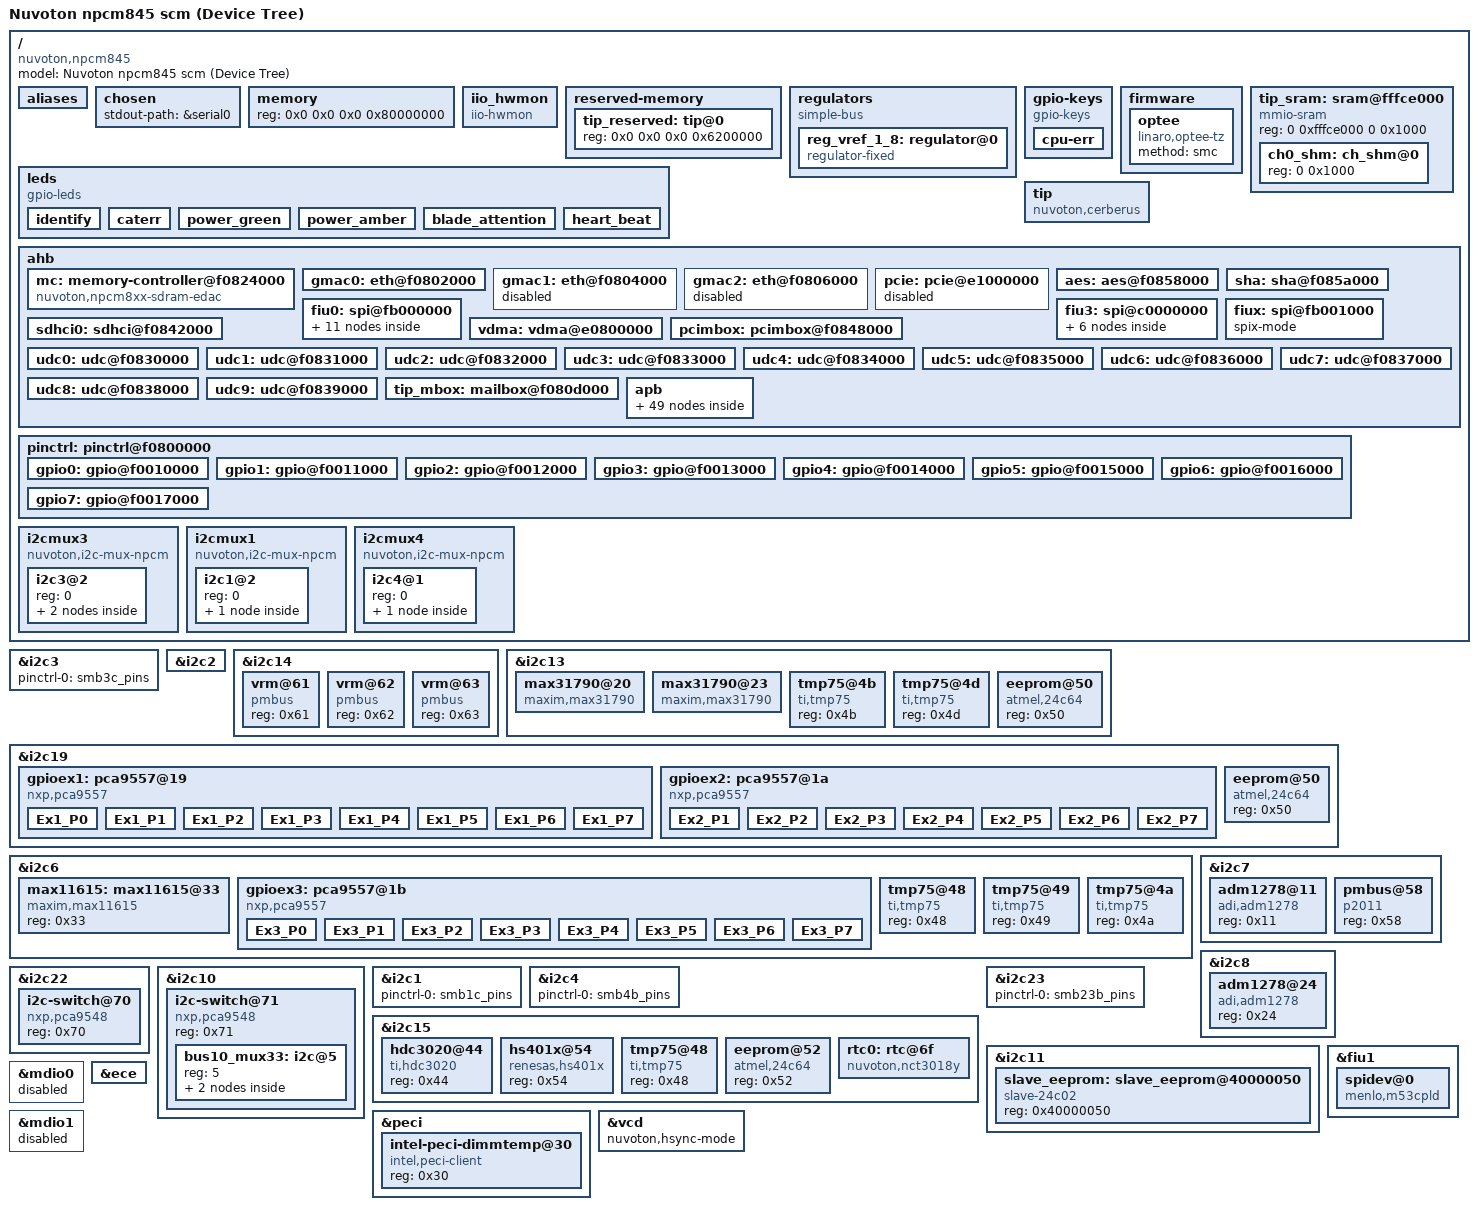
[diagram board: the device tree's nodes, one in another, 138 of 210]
// SPDX-License-Identifier: GPL-2.0
// Copyright (c) 2018 Nuvoton Technology tomer.maimon@nuvoton.com
// Copyright 2018 Google, Inc.

/dts-v1/;
#include "nuvoton-npcm845.dtsi"
#include "nuvoton-npcm845-pincfg-evb.dtsi"
#include <dt-bindings/thermal/thermal.h>
#include <dt-bindings/i2c/i2c.h>

/ {
	model = "Nuvoton npcm845 scm (Device Tree)";
	compatible = "nuvoton,npcm845";

	aliases {
		serial0 = &serial0;
		serial1 = &serial1;
		serial2 = &serial2;
		serial3 = &serial3;
		serial4 = &serial4;
		serial5 = &serial5;
		ethernet0 = &gmac0;
		ethernet1 = &gmac2;
		udc0 = &udc0;
		udc1 = &udc1;
		udc2 = &udc2;
		udc3 = &udc3;
		udc4 = &udc4;
		udc5 = &udc5;
		udc6 = &udc6;
		udc7 = &udc7;
		udc8 = &udc8;
		udc9 = &udc9;
		i2c1 = &i2c3;
		i2c2 = &i2c2;
		i2c3 = &i2c14;
		i2c4 = &i2c13;
		i2c5 = &i2c19;
		i2c6 = &i2c6;
		i2c7 = &i2c7;
		i2c8 = &i2c8;
		i2c9 = &i2c22;
		i2c10 = &i2c10;
		i2c11 = &i2c1;
		i2c12 = &i2c4;
		i2c15 = &i2c15;
		i2c16 = &i2c23;
		i2c17 = &i2c11;
		fiu0 = &fiu0;
		fiu1 = &fiu3;
		fiu2 = &fiux;
		fiu3 = &fiu1;
	};

	chosen {
		stdout-path = &serial0;
	};

	memory {
		reg = <0x0 0x0 0x0 0x80000000>;
	};

	iio_hwmon {
		compatible = "iio-hwmon";
		io-channels = <&adc 0>, <&adc 1>, <&adc 2>, <&adc 3>,
			      <&max11615 0>, <&max11615 1>, <&max11615 2>,
			      <&max11615 3>, <&max11615 4>, <&max11615 5>,
			      <&max11615 6>, <&max11615 7>;
	};

	reserved-memory {
		#address-cells = <2>;
		#size-cells = <2>;
		ranges;

		tip_reserved: tip@0 {
		reg = <0x0 0x0 0x0 0x6200000>;
		};

	};

	regulators {
		compatible = "simple-bus";
		#address-cells = <1>;
		#size-cells = <0>;

		reg_vref_1_8: regulator@0 {
			compatible = "regulator-fixed";
			reg = <0>;
			regulator-name = "vref_1_8v";
			regulator-min-microvolt = <1800000>;
			regulator-max-microvolt = <1800000>;
		};
	};

	leds {
		compatible = "gpio-leds";

		identify {
			label = "identify";
			gpios = <&gpio1 30 GPIO_ACTIVE_HIGH>; /* gpio62 */
		};

		caterr {
			label = "caterr";
			gpios = <&gpio2 12 GPIO_ACTIVE_HIGH>; /* gpio76 */
		};

		power_green {
			label = "power_green";
			gpios = <&gpio1 12 GPIO_ACTIVE_HIGH>; /* gpio44 */
		};

		power_amber {
			label = "power_amber";
			gpios = <&gpio1 13 GPIO_ACTIVE_HIGH>; /* gpio45 */
		};

		blade_attention {
			label = "blade_attention";
			gpios = <&gpio1 14 GPIO_ACTIVE_HIGH>; /* gpio46 */
		};

		heart_beat {
			label = "heart_beat";
			gpios = <&gpio7 4 GPIO_ACTIVE_HIGH>; /* gpio228 */
		};
	};

	gpio-keys {
		compatible = "gpio-keys";
		cpu-err {
			label = "cpu-err";
			gpios = <&gpio2 12 GPIO_ACTIVE_LOW>;
			linux,code = <27>;
		};
	};

	firmware {
		optee {
			compatible = "linaro,optee-tz";
			method = "smc";
		};
	};

	tip_sram: sram@fffce000 {
		compatible = "mmio-sram";
		reg = <0 0xfffce000 0 0x1000>;
		#address-cells = <1>;
		#size-cells = <1>;
		ranges = <0 0 0xfffce000 0x1000>;
		ch0_shm: ch_shm@0 {
			reg = <0 0x1000>;
		};
	};

	tip {
		compatible = "nuvoton,cerberus";
		mboxes = <&tip_mbox 0 16>; /*channel 0, 16th doorbell */
		mbox-names = "cerberus";
		shmem = <&ch0_shm>;
		status = "okay";
	};

	ahb {
		mc: memory-controller@f0824000 {
			compatible = "nuvoton,npcm8xx-sdram-edac";
			reg = <0x0 0xf0824000 0x0 0x1000>;
			interrupts = <GIC_SPI 25 IRQ_TYPE_LEVEL_HIGH>;
			status = "okay";
		};


		gmac0: eth@f0802000 {
			phy-mode = "sgmii";
			npcm,sgmii-an;
			snps,eee-force-disable;
			status = "okay";
		};

		gmac1: eth@f0804000 {
			phy-mode = "rgmii-id";
			snps,eee-force-disable;
			status = "disable";
		};

		gmac2: eth@f0806000 {
			pinctrl-names = "default";
			pinctrl-0 = <&r1_pins
					&r1oen_pins>;

			status = "disabled";
			use-ncsi;
		};

		pcie: pcie@e1000000 {
			status = "disabled";
		};

		aes: aes@f0858000 {
			status = "okay";
		};

		sha: sha@f085a000 {
			status = "okay";
		};

		fiu0: spi@fb000000 {
			status = "okay";
			spi-nor@0 {
				compatible = "jedec,spi-nor";
				#address-cells = <1>;
				#size-cells = <1>;
				spi-rx-bus-width = <2>;
				spi-tx-bus-width = <2>;
				reg = <0>;
				spi-max-frequency = <40000000>;
				partitions@80000000 {
					compatible = "fixed-partitions";
					#address-cells = <1>;
					#size-cells = <1>;
					bmc@0{
						label = "bmc";
						reg = <0x00000000 0x04000000>;
					};
					u-boot@0 {
						label = "u-boot";
						reg = <0x00000000 0x007C0000>;
					};
					u-boot-env@7c0000{
						label = "u-boot-env";
						reg = <0x007C0000 0x00040000>;
					};
					kernel@800000 {
						label = "kernel";
						reg = <0x00800000 0x00800000>;
					};
					rofs@1000000 {
						label = "rofs";
						reg = <0x01000000 0x02C00000>;
					};
					rwfs@3c00000 {
						label = "rwfs";
						reg = <0x03C00000 0x003E0000>;
					};
				};
			};
			spi-nor@1 {
				compatible = "jedec,spi-nor";
				#address-cells = <1>;
				#size-cells = <1>;
				reg = <1>;
				spi-rx-bus-width = <2>;
				spi-tx-bus-width = <2>;
				spi-max-frequency = <40000000>;
				partitions@88000000 {
					compatible = "fixed-partitions";
					#address-cells = <1>;
					#size-cells = <1>;
					spare@0 {
						label = "spi0-cs1-spare";
						reg = <0x0 0x04000000>;
					};
				};
			};
		};

		fiu3: spi@c0000000 {
			status = "okay";
			pinctrl-0 = <&spi3_pins>, <&spi3quad_pins>, <&spi3cs1_pins>;
			spi-nor@0 {
				compatible = "jedec,spi-nor";
				#address-cells = <1>;
				#size-cells = <1>;
				reg = <0>;
				spi-max-frequency = <25000000>;
				partitions@A0000000 {
					compatible = "fixed-partitions";
					#address-cells = <1>;
					#size-cells = <1>;
					system1@0 {
						label = "pnor";
						reg = <0x0 0x0>;
					};
				};
			};
			spi-nor@1 {
				compatible = "jedec,spi-nor";
				#address-cells = <1>;
				#size-cells = <1>;
				reg = <1>;
				spi-max-frequency = <25000000>;
				partitions@A8000000 {
					compatible = "fixed-partitions";
					#address-cells = <1>;
					#size-cells = <1>;
					system1@0 {
						label = "image-bios-1";
						reg = <0x0 0x0>;
					};
				};
			};
		};

		fiux: spi@fb001000 {
			spix-mode;
		};

		sdhci0: sdhci@f0842000 {
			status = "okay";
		};

		vdma: vdma@e0800000 {
			status = "okay";
		};

		pcimbox: pcimbox@f0848000 {
			status = "okay";
		};

		udc0:udc@f0830000 {
			status = "okay";
		};

		udc1:udc@f0831000 {
			status = "okay";
		};

		udc2:udc@f0832000 {
			status = "okay";
		};

		udc3:udc@f0833000 {
			status = "okay";
		};

		udc4:udc@f0834000 {
			status = "okay";
		};

		udc5:udc@f0835000 {
			status = "okay";
		};

		udc6:udc@f0836000 {
			status = "okay";
		};

		udc7:udc@f0837000 {
			status = "okay";
		};

		udc8:udc@f0838000 {
			status = "okay";
		};

		udc9:udc@f0839000 {
			status = "okay";
		};

		tip_mbox: mailbox@f080d000 {
			status = "okay";
		};

		apb {
			lpc_kcs: lpc_kcs@7000 {
				kcs1: kcs1@0 {
					status = "okay";
				};

				kcs2: kcs2@0 {
					status = "okay";
				};

				kcs3: kcs3@0 {
					status = "okay";
				};
			};

			lpc_host: lpc_host@7000 {
				lpc_bpc: lpc_bpc@40 {
					monitor-ports = <0x80>;
					bpc-en-dwcapture;
					status = "okay";
				};
			};

			serial0: serial@0 {
				status = "okay";
			};

			serial1: serial@1000 {
				status = "okay";
			};

			serial2: serial@2000 {
				status = "okay";
			};

			serial3: serial@3000 {
				status = "okay";
			};

			serial4: serial@4000 {
				status = "okay";
			};

			serial5: serial@5000 {
				status = "okay";
			};

			serial6: serial@6000 {
				status = "okay";
			};

			rng: rng@b000 {
				status = "okay";
			};

			adc: adc@c000 {
				/* enable external vref */
				vref-supply = <&reg_vref_1_8>;
				#io-channel-cells = <1>;
				status = "okay";
			};

			watchdog1: watchdog@901c {
				nuvoton,reset-priority = <155>;
				nuvoton,card-reset-type = "porst";
				nuvoton,ext1-reset-type = "wd1";
				nuvoton,ext2-reset-type = "sw2";
				status = "okay";
			};

			sgpio1: sgpio@101000{
				status = "okay";
			};

			sgpio2: sgpio@102000 {
				/* Reserved out = 12,14,24,28,32;Reserved in = 35  */
				/* NMI_OUT=sgpio 7 */
				status = "okay";
				bus-frequency = <8000000>;
				nuvoton,output-ngpios = <38>;
				nuvoton,input-ngpios = <62>;
				gpio-line-names =
					"TPM_BMC_ALERT_N","BMC_PCH_FNM","FM_SPD_SWITCH_CTRL_N","SMB_SLIVER_RST_BMC_N","PWRBRK_SLI_OE_N","FM_ME_RECOVERY_N","RST_BMC_RTCRST","NMI_OUT",
					"PSU2_ALERT_EN_N","BMC_NVDIMM_PRSNT_N","FM_SMM_CRASHDUMP","RST_PE_E1S_I2C_MUX_N","","INLET_SENSE_RESET_N","","RST_MIC_MUX_N",
					"FM_UV_ADR_TRIGGER_EN","FM_FORCE_ADR","FM_ADR_ACK","CPU_FBRK_OUT_N","PMB_ALERT_EN_N","FM_BIOS_MRC_DEBUG_MSG_DIS","FM_UEFI_DEBUG_MSG_EN","BMC_FORCE_NM_THROTTLE_N",
					"","FM_BMC_CRASHLOG_TRIG_SEL","FM_BMC_SCI_N","FM_PWRBRK_N","","RM_THROTTLE_EN_N","FM_CPLD_BMC_PWRDN_N","MB_JTAG_NTRST",
					"","PDB_ALERT3_EN_N","PDB_ALERT2_EN_N","PDB_ALERT1_EN_N","FM_UART2_FPGA_SELECT","FM_USB_CPU_FPGA_SELECT",
					"BMC_NODE_ID_0","BMC_NODE_ID_1","BMC_NODE_ID_2","BMC_NODE_ID_3","BMC_NODE_ID_4","BMC_NODE_ID_5","P0_SKTOCC_N","P1_SKTOCC_N",
					"P0_PROCHOT_N","P1_PROCHOT_N","FM_CPU0_THERMTRIP_LATCH_LVT3_N","FM_CPU1_THERMTRIP_LATCH_LVT3_N","H_CPU0_MEMHOT_OUT_LVC1_N","H_CPU1_MEMHOT_OUT_LVC1_N","P0_MEM_VRHOT_N","P1_MEM_VRHOT_N",
					"P0_BMC_MEMTRIP_N","P1_BMC_MEMTRIP_N","FM_CPU0_ERR0_LVT3_N","FM_CPU0_ERR1_LVT3_N","FM_CPU0_ERR2_LVT3_N","SMB_BMC_ALERT1_N","SMB_BMC_ALERT2_N","SMB_BMC_ALERT3_N",
					"SMB_BMC_ALERT4_N","SMB_BMC_ALERT5_N","SMB_BMC_ALERT6_N","SMB_BMC_ALERT7_N","SMB_BMC_ALERT8_N","SMB_BMC_ALERT9_N","SMB_BMC_ALERT10_N","SMB_BMC_ALERT11_N",
					"SMB_BMC_ALERT12_N","IRQ_HSC_FAULT_N","FM_DBP_PRESENT_N","","FM_PCHHOT_N","PSU1_ALERT_N","PDB_ALERT1_N","PDB_ALERT2_N",
					"PWRGD_CPU0_LVC3","IRQ_PVCCIN_CPU0_VRHOT_LVC3_N","IRQ_PVCCIN_CPU1_VRHOT_LVC3_N","FM_ADR_TRIGGER_N","FM_ADR_COMPLETE_BMC","PSU1_BLADE_EN_N","FM_CD_INIT_ERROR_0","FM_CD_INIT_ERROR_1",
					"FM_PVCCIN_CPU0_PWR_IN_ALERT_N","FM_PVCCIN_CPU1_PWR_IN_ALERT_N","POWER_FAIL_R_N","SYS_PWROK_BMC","FM_SLPS3_R_N","FM_SLPS4_S5_N","FM_REMOTE_DEBUG_EN_N","PWRGD_CPU1_LVC3",
					"HPM_BRD_REV_ID0","HPM_BRD_REV_ID1","HPM_BRD_REV_ID2","GLB_RST_WARN_N","BMC_RSTBTN_OUT_N","PSU2_ALERT_N";
			};
			jtm1: jtm@208000 {
				status = "okay";
			};

			jtm2: jtm@209000 {
				status = "okay";
			};

			i3c0: i3c@fff10000 {
				status = "okay";
				i2c-scl-hz = <400000>;
				i3c-scl-hz = <4000000>;
				jedec,jesd403;
				tsA0@0x10 {
					reg = <0x10 0x4cc 0x51110010>;
				};
				tsB0@0x11 {
					reg = <0x11 0x4cc 0x51110011>;
				};
				tsC0@0x12 {
					reg = <0x12 0x4cc 0x51110012>;
				};
				tsD0@0x13 {
					reg = <0x13 0x4cc 0x51110013>;
				};
				tsE0@0x14 {
					reg = <0x14 0x4cc 0x51110014>;
				};
				tsF0@0x15 {
					reg = <0x15 0x4cc 0x51110015>;
				};
			};

			i3c1: i3c@fff11000 {
				status = "okay";
				i2c-scl-hz = <400000>;
				i3c-scl-hz = <4000000>;
				jedec,jesd403;
				tsA1@0x10 {
					reg = <0x10 0x4cc 0x51110010>;
				};
				tsB1@0x11 {
					reg = <0x11 0x4cc 0x51110011>;
				};
				tsC1@0x12 {
					reg = <0x12 0x4cc 0x51110012>;
				};
				tsD1@0x13 {
					reg = <0x13 0x4cc 0x51110013>;
				};
				tsE1@0x14 {
					reg = <0x14 0x4cc 0x51110014>;
				};
				tsF1@0x15 {
					reg = <0x15 0x4cc 0x51110015>;
				};
			};

			i3c2: i3c@fff12000 {
				status = "okay";
				i2c-scl-hz = <400000>;
				i3c-scl-hz = <4000000>;
				jedec,jesd403;
				mux@0x0f {
					reg = <0x0f 0x3c0 0x00000000>;
				};
				tsG0@0x10 {
					reg = <0x10 0x4cc 0x51110010>;
				};
				tsH0@0x11 {
					reg = <0x11 0x4cc 0x51110011>;
				};
				tsI0@0x12 {
					reg = <0x12 0x4cc 0x51110012>;
				};
				tsJ0@0x13 {
					reg = <0x13 0x4cc 0x51110013>;
				};
				tsK0@0x14 {
					reg = <0x14 0x4cc 0x51110014>;
				};
				tsL0@0x15 {
					reg = <0x15 0x4cc 0x51110015>;
				};
			};
			
			i3c3: i3c@fff13000 {
				status = "okay";
				i2c-scl-hz = <400000>;
				i3c-scl-hz = <4000000>;
				jedec,jesd403;
				tsG1@0x10 {
					reg = <0x10 0x4cc 0x51110010>;
				};
				tsH1@0x11 {
					reg = <0x11 0x4cc 0x51110011>;
				};
				tsI1@0x12 {
					reg = <0x12 0x4cc 0x51110012>;
				};
				tsJ1@0x13 {
					reg = <0x13 0x4cc 0x51110013>;
				};
				tsK1@0x14 {
					reg = <0x14 0x4cc 0x51110014>;
				};
				tsL1@0x15 {
					reg = <0x15 0x4cc 0x51110015>;
				};
			};
		};
	};

 	pinctrl: pinctrl@f0800000 {
		pinctrl-names = "default";
		pinctrl-0 = <
				&espi_pins
				&mmcrst_pins
				&pin240_slew
				&pin241_slew
				&pin242_slew
				&pin243_slew
				&pin244_slew
				&pin245_slew
				&pin246_slew
				&pin247_slew
				&pin4_slew
				&pin5_slew
				&pin6_slew
				&pin7_slew
				&spix_pins
				&pin110_slew
				&pin111_slew
				&pin112_slew
				&pin113_slew
				&pin208_slew
				&pin209_slew
				&pin210_slew
				&pin211_slew
				&pin212_slew
				&pin213_slew
				&pin214_slew
				&pin215_slew
				&pin216_slew
				&pin217_slew
				&pin250_slew
				&ddr_pins>;

		gpio0: gpio@f0010000 {
			/*IRQ_NMI_EVENT_R_N=gpio13,FM_BIOS_POST_CMPLT_N=gpio15*/
			interrupt-controller;
			#interrupt-cells = <2>;
			gpio-line-names =
			/*0-31*/
			"","","","","","","","",
			"JTAG_BMC_OE_N","","","","FM_BMC_READY_N","NMI_BUTTON","","POST_COMPLETE",
			"JTAG_JM1_EN","SENSE_ALERT_N","","","","","","",
			"","","","BMC_PORT0_RST_REQ0_N","","SPI_BMC_CPLD_FPGA_SEL","","";
		};

		gpio1: gpio@f0011000 {
			interrupt-controller;
			gpio-line-names =
			/*32-63*/
			"","","","PSU_ALERT_N","HSC_GPIO2_BMC_N","","","CD_INIT_ERROR_1",
			"","","","","BMC_LED_PWR_GRN","BMC_LED_PWR_AMBER","FM_BMC_FAULT_LED","RST_BMC_DP_N",
			"","","","","","","","",
			"","FM_ADR_ACK_R","","","","DP_INTP_BMC","BMC_ID_LED","";
		};
		gpio2: gpio@f0012000 {
			/* P3V_BAT_EN=gpio83 */
			interrupt-controller;
			#interrupt-cells = <2>;
			gpio-line-names =
			/*64-95*/
			"CURRENT_ALERT_N","VOLTAGE_ALERT_N","PSU2_PS_ON_N","IRQ_SMI_ACTIVE_BMC_N","FM_THROTTLE_IN_BMC_N","RM_THROTTLE_SW_BMC_N","SGPIO_INTR_N","DP_PWR_EN",
			"FM_PCH_BMC_THERMTRIP_N","P1_DISABLE_COD_N","IRQ_PVCCD_CPU0_VRHOT_N","IRQ_PVCCD_CPU1_VRHOT_N","BMC_LED_CATERR","PWRGD_P12V_AUX","LPC_ENABLE_ESPI_N","USB_EX1_OC_N_BMC",
			"","FM_BMC_CRASHLOG_TRIG_N","","P3V_BAT_EN","FM_PCH_THROTTLE_R_N","","","",
			"","RST_PLTRST_N","","CPU_CATERR_LVC1_N","CPLD_IRQ_N","PSU_ALERT_EN_N","RST_BMC_RTCRST_R","";
		};

		gpio3: gpio@f0013000 {
			/*  */
			interrupt-controller;
			#interrupt-cells = <2>;
			gpio-line-names =
			/*96-127*/
			"","","","","","","","",
			"","","","","","","","",
			"","","LION_FATAL_ERR_N_R","LION_TEMP_ERR_N_R","VIRTUAL_RESEAT","DBP_CPU_PREQ_R_N","","",
			"H_BMC_PRDY_R_N","HPM_FW_RECOVERY_R","SGPIO_RESET_N","IRQ_0_R","","","","";
		};
		gpio4: gpio@f0014000 {
			interrupt-controller;
			gpio-line-names =
			/*128-159*/
			"","","","","","","","",
			"","","","","","","","",
			"FM_FORCE_ADR","RM_THROTTLE_N","CPU_UNRMCA_N","CPU_RMCA_N","","","","",
			"","","","","","","","";
		};
		gpio5: gpio@f0015000 {
			/* POWER_OUT=gpio190 */
			gpio-line-names =
			/*160-191*/
			"BMC_PWRCAP_BMC_N","","HSC_GPIO1_BMC_N","","","","","",
			"","","","","","","","",
			"","","","","","","","",
			"","","","","","","POWER_OUT","";
		};
		gpio6: gpio@f0016000 {
			gpio-line-names =
			/*192-223*/
			"","","","FM_TPM_SPI_MUX_CTRL_R","FM_JTAG_TCK_MUX_SEL","JTAG_MUX_SELECT","IRQ_BMC_SMI_R_N","FM_BIOS_SPI_BMC_CTRL",
			"RST_RSMRST_N","","I2C0_LION_ALT_N","","","","","",
			"","","","","","","","",
			"","","PORT0_RST_WDT_N","PORT0_RST_WDT1_N","IRQ_BMC_CPU_NMI","","","";
		};
		gpio7: gpio@f0017000 {
			/* PS_PWROK=gpio233, RESET_BUTTON=gpio234, RESET_OUT=gpio235 */
			gpio-line-names =
			/*224-255*/
			"","","","","FM_BMC_HEARTBEAT_R","","","IRQ_PMBUS_ALERT_N",
			"","PS_PWROK","RESET_BUTTON","RESET_OUT","","","","",
			"","","","","","","","",
			"","","","","","","","";
		};
	};

	i2cmux3 {
		compatible = "nuvoton,i2c-mux-npcm";
		#address-cells = <1>;
		#size-cells = <0>;

		status = "okay";
		i2c-parent = <&i2c3>;
		syscon = <&gcr>;
		nuvoton,i2c-number = <3>;
		i2c_segment_number = <2>;

		i2c3@2 {
			reg = <0>;
			#address-cells = <1>;
			#size-cells = <0>;
			status = "okay";

			sbrmi@3c {
				compatible = "amd,sbrmi";
				reg = <0x3c>;
				status = "okay";
			};

			sbtsi@4c {
				compatible = "amd,sbtsi";
				reg = <0x4c>;
				status = "okay";
			};
		};
	};
	i2cmux1 {
		compatible = "nuvoton,i2c-mux-npcm";
		#address-cells = <1>;
		#size-cells = <0>;

		status = "okay";
		i2c-parent = <&i2c1>;
		syscon = <&gcr>;
		nuvoton,i2c-number = <1>;
		i2c_segment_number = <2>;

		i2c1@2 {
			reg = <0>;
			#address-cells = <1>;
			#size-cells = <0>;
			status = "okay";

			i2c-mux@72 {
				compatible = "nxp,pca9546";
				#address-cells = <1>;
				#size-cells = <0>;
				reg = <0x72>;
				status = "okay";
			};
		};
	};
	i2cmux4 {
		compatible = "nuvoton,i2c-mux-npcm";
		#address-cells = <1>;
		#size-cells = <0>;

		status = "okay";
		i2c-parent = <&i2c4>;
		syscon = <&gcr>;
		nuvoton,i2c-number = <4>;
		i2c_segment_number = <1>;

		i2c4@1 {
			reg = <0>;
			#address-cells = <1>;
			#size-cells = <0>;
			status = "okay";

			i2c-mux@74 {
				compatible = "nxp,pca9546";
				#address-cells = <1>;
				#size-cells = <0>;
				reg = <0x74>;
				status = "okay";
			};
		};
	};

};

&i2c3 { //MM1
	pinctrl-0 = <&smb3c_pins>;
	status = "okay";
};

&i2c2 { //MM2
	status = "okay";
};

&i2c14 { //MM3
	status = "okay";
	vrm@61 {
		compatible = "pmbus";
		reg = <0x61>;
	};

	vrm@62 {
		compatible = "pmbus";
		reg = <0x62>;
	};

	vrm@63 {
		compatible = "pmbus";
		reg = <0x63>;
	};
};

&i2c13 { //MM4
	status = "okay";
	max31790@20 {
		compatible = "maxim,max31790";
		reg = <0x20>;
		fan-mode = "pwm";
                fanconfig1 = <0x0>;
	};
	max31790@23 {
		compatible = "maxim,max31790";
		reg = <0x23>;
		fan-mode = "fan";
                fanconfig1 = <0x99>;
                fanconfig2 = <0x99>;
                fanconfig3 = <0x99>;
                fanconfig4 = <0x99>;
                fanconfig5 = <0x99>;
                fanconfig6 = <0x99>;
                fandynamics1 = <0x8c>;
                fandynamics2 = <0x8c>;
                fandynamics3 = <0x8c>;
                fandynamics4 = <0x8c>;
                fandynamics5 = <0x8c>;
                fandynamics6 = <0x8c>;
	};
	tmp75@4b {
		compatible = "ti,tmp75";
		reg = <0x4b>;
	};
	tmp75@4d {
		compatible = "ti,tmp75";
		reg = <0x4d>;
	};
	eeprom@50 {
		compatible = "atmel,24c64";
		reg = <0x50>;
	};
};

&i2c19 { //MM5
	status = "okay";
	gpioex1: pca9557@19 {
		compatible = "nxp,pca9557";
		reg = <0x19>;
		gpio-controller;
		#gpio-cells = <2>;
		Ex1_P0 {
			gpio-hog;
			gpios = <0 0>;
			input;
			line-name = "CPU_VR_MAIN_2ND_1";
		};
		Ex1_P1 {
			gpio-hog;
			gpios = <1 0>;
			input;
			line-name = "SMB_M2_S2_ALERT_N";
		};
		Ex1_P2 {
			gpio-hog;
			gpios = <2 0>;
			input;
			line-name = "SMB_M2_S1_ALERT_N";
		};
		Ex1_P3 {
			gpio-hog;
			gpios = <3 0>;
			output-low;
			line-name = "P3V3_M2_S2_BMC_EN_N";
		};
		Ex1_P4 {
			gpio-hog;
			gpios = <4 0>;
			output-low;
			line-name = "P3V3_M2_S1_BMC_EN_N";
		};
		Ex1_P5 {
			gpio-hog;
			gpios = <5 0>;
			input;
			line-name = "RTM1_INT_N";
		};
		Ex1_P6 {
			gpio-hog;
			gpios = <6 0>;
			input;
			line-name = "RTM2_INT_N";
		};
		Ex1_P7 {
			gpio-hog;
			gpios = <7 0>;
			input;
			line-name = "CPU_VR_MAIN_2ND_2";
		};
	};
	gpioex2: pca9557@1a {
		compatible = "nxp,pca9557";
		reg = <0x1a>;
		gpio-controller;
		#gpio-cells = <2>;
		Ex2_P1 {
			gpio-hog;
			gpios = <1 0>;
			output-high;
			line-name = "SMB_ES1_RST_N";
		};
		Ex2_P2 {
			gpio-hog;
			gpios = <2 0>;
			output-high;
			line-name = "SMB_ES2_RST_N";
		};
		Ex2_P3 {
			gpio-hog;
			gpios = <3 0>;
			output-high;
			line-name = "SMB_ES3_RST_N";
		};
		Ex2_P4 {
			gpio-hog;
			gpios = <4 0>;
			output-high;
			line-name = "SMB_ES4_RST_N";
		};
		Ex2_P5 {
			gpio-hog;
			gpios = <5 0>;
			output-high;
			line-name = "SMB_ES5_RST_N";
		};
		Ex2_P6 {
			gpio-hog;
			gpios = <6 0>;
			output-low;
			line-name = "P5V_USB_INT1_EN_N";
		};
		Ex2_P7 {
			gpio-hog;
			gpios = <7 0>;
			input;
			line-name = "FM_USB_INT1_LVC3_OC_N";
		};
	};
	eeprom@50 {
		compatible = "atmel,24c64";
		reg = <0x50>;
	};
};

&i2c6 { //MM6
	status = "okay";
	max11615: max11615@33 {
		compatible = "maxim,max11615";
		#io-channel-cells = <1>;
		reg = <0x33>;
	};
	gpioex3: pca9557@1b {
		compatible = "nxp,pca9557";
		reg = <0x1b>;
		gpio-controller;
		#gpio-cells = <2>;
		Ex3_P0 {
			gpio-hog;
			gpios = <0 0>;
			output-high;
			line-name = "NIC_POWER_EN";
		};
		Ex3_P1 {
			gpio-hog;
			gpios = <1 0>;
			output-high;
			line-name = "SMB_ES6_RST_N";
		};
		Ex3_P2 {
			gpio-hog;
			gpios = <2 0>;
			output-high;
			line-name = "SMB_ES7_RST_N";
		};
		Ex3_P3 {
			gpio-hog;
			gpios = <3 0>;
			output-high;
			line-name = "SMB_ES8_RST_N";
		};
		Ex3_P4 {
			gpio-hog;
			gpios = <4 0>;
			output-high;
			line-name = "SMB_ES9_RST_N";
		};
		Ex3_P5 {
			gpio-hog;
			gpios = <5 0>;
			output-high;
			line-name = "SMB_ES10_RST_N";
		};
		Ex3_P6 {
			gpio-hog;
			gpios = <6 0>;
			output-high;
			line-name = "SMB_NIC_RST_N";
		};
		Ex3_P7 {
			gpio-hog;
			gpios = <7 0>;
			output-high;
			line-name = "SMB_SLOT3X16_RST_N";
		};
	};
	tmp75@48 {
		compatible = "ti,tmp75";
		reg = <0x48>;
	};
	tmp75@49 {
		compatible = "ti,tmp75";
		reg = <0x49>;
	};
	tmp75@4a {
		compatible = "ti,tmp75";
		reg = <0x4a>;
	};
};

&i2c7 { //MM7
	status = "okay";
	adm1278@11 {
		compatible = "adi,adm1278";
		reg = <0x11>;
	};
	pmbus@58 {
		compatible = "p2011";
		reg = <0x58>;
	};
};

&i2c8 { //MM8
	status = "okay";
	adm1278@24 {
		compatible = "adi,adm1278";
		reg = <0x24>;
	};
};

&i2c22 { //MM9
	status = "okay";
	i2c-switch@70 {
		compatible = "nxp,pca9548";
		#address-cells = <1>;
		#size-cells = <0>;
		reg = <0x70>;
	};
};

&i2c10 { //MM10
	status = "okay";
	i2c-switch@71 {
		compatible = "nxp,pca9548";
		#address-cells = <1>;
		#size-cells = <0>;
		reg = <0x71>;
		bus10_mux33: i2c@5 {
			#address-cells = <1>;
			#size-cells = <0>;
			reg = <5>;
			tmp461@4c {
				compatible = "ti,tmp461";
				reg = <0x4c>;
			};
			max16550@42 {
				compatible = "max16550";
				reg = <0x42>;
			};
		};
	};
};

&i2c1 { //MM11
	pinctrl-0 = <&smb1c_pins>;
	status = "okay";
};

&i2c4 { //MM12
	pinctrl-0 = <&smb4b_pins>;
	status = "okay";
};

&i2c15 { //MM15
	status = "okay";
	hdc3020@44 {
		compatible = "ti,hdc3020";
		reg = <0x44>;
	};

	hs401x@54 {
		compatible = "renesas,hs401x";
		reg = <0x54>;
	};
	
	tmp75@48 {
		compatible = "ti,tmp75";
		reg = <0x48>;
	};

	eeprom@52 {
		compatible = "atmel,24c64";
		reg = <0x52>;
	};

	rtc0: rtc@6f {
		compatible = "nuvoton,nct3018y";
		reg = <0x6f>;
		#clock-cells = <0>;

		interrupt-parent = <&gpio3>;
		interrupts = <1 IRQ_TYPE_EDGE_FALLING>; /* gpio 97 */
		interrupt-names = "irq";
		wakeup-source;
	};
};

&i2c23 { //MM16
	pinctrl-0 = <&smb23b_pins>;
	status = "okay";
};

&i2c11 { //Internal eeprom for DVO
	status = "okay";
	slave_eeprom: slave_eeprom@40000050 {
		compatible = "slave-24c02";
		reg = <0x40000050>;
		status = "okay";
	};
};

&fiu1 {
	status = "okay";
	spidev@0 {
		status = "okay";
		compatible = "menlo,m53cpld";
		spi-max-frequency = <2000000>;
		reg = <0>;
	};
};

&mdio0 {
	status = "disabled";
};

&mdio1 {
	status = "disabled";
};

&peci {
	cmd-timeout-ms = <1000>;
	npcm,pull-down = <0>;
	npcm,host-neg-bit-rate = <15>;
	status = "okay";
	intel-peci-dimmtemp@30 {
		compatible = "intel,peci-client";
		reg = <0x30>;
		status = "okay";
	};
};

&vcd {
	nuvoton,hsync-mode;
	status = "okay";
};
&ece {
	status = "okay";
};
